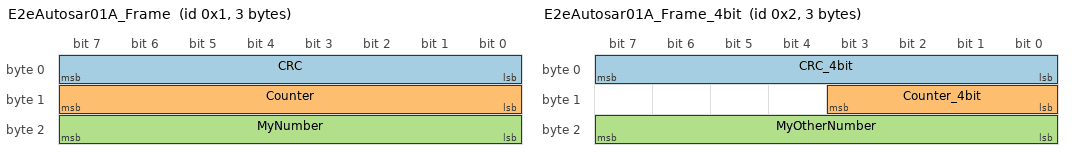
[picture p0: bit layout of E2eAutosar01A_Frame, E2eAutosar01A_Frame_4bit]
BO_ 1 E2eAutosar01A_Frame: 3 NONE
 SG_ CRC : 7|8@0+ (1.0, 0.0) [0.0|255.0] "NoUnit" ECUA
 SG_ Counter : 15|8@0+ (1.0, 0.0) [0.0|15.0] "NoUnit" ECUA
 SG_ MyNumber : 23|8@0+ (1.0, 0.0) [0.0|255.0] "NoUnit" ECUA

BO_ 2 E2eAutosar01A_Frame_4bit: 3 NONE
 SG_ CRC_4bit : 7|8@0+ (1.0, 0.0) [0.0|255.0] "NoUnit" ECUA
 SG_ Counter_4bit : 11|4@0+ (1.0, 0.0) [0.0|15.0] "NoUnit" ECUA
 SG_ MyOtherNumber : 23|8@0+ (1.0, 0.0) [0.0|255.0] "NoUnit" ECUA

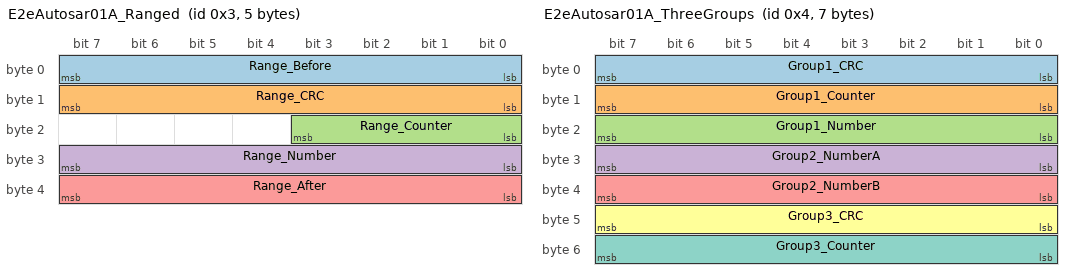
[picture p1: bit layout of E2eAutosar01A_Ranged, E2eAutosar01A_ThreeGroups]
BO_ 3 E2eAutosar01A_Ranged: 5 NONE
 SG_ Range_Before : 7|8@0+ (1.0, 0.0) [0.0|255.0] "NoUnit" ECUA
 SG_ Range_CRC : 15|8@0+ (1.0, 0.0) [0.0|255.0] "NoUnit" ECUA
 SG_ Range_Counter : 19|4@0+ (1.0, 0.0) [0.0|15.0] "NoUnit" ECUA
 SG_ Range_Number : 31|8@0+ (1.0, 0.0) [0.0|255.0] "NoUnit" ECUA
 SG_ Range_After : 39|8@0+ (1.0, 0.0) [0.0|255.0] "NoUnit" ECUA

BO_ 4 E2eAutosar01A_ThreeGroups: 7 NONE
 SG_ Group1_CRC : 7|8@0+ (1.0, 0.0) [0.0|255.0] "NoUnit" ECUA
 SG_ Group1_Counter : 15|8@0+ (1.0, 0.0) [0.0|255.0] "NoUnit" ECUA
 SG_ Group1_Number : 23|8@0+ (1.0, 0.0) [0.0|255.0] "NoUnit" ECUA
 SG_ Group2_NumberA : 31|8@0+ (1.0, 0.0) [0.0|255.0] "NoUnit" ECUA
 SG_ Group2_NumberB : 39|8@0+ (1.0, 0.0) [0.0|255.0] "NoUnit" ECUA
 SG_ Group3_CRC : 47|8@0+ (1.0, 0.0) [0.0|255.0] "NoUnit" ECUA
 SG_ Group3_Counter : 55|8@0+ (1.0, 0.0) [0.0|255.0] "NoUnit" ECUA

BA_ "GenMsgCycleTime" BO_ 1 1000.000;
BA_ "GenMsgCycleTime" BO_ 2 1000.000;
BA_ "GenMsgCycleTime" BO_ 3 2000.000;
BA_ "GenMsgCycleTime" BO_ 4 3000.000;

BA_DEF_ BO_ "GenMsgCycleTime" FLOAT 0 300000; // [ms]
